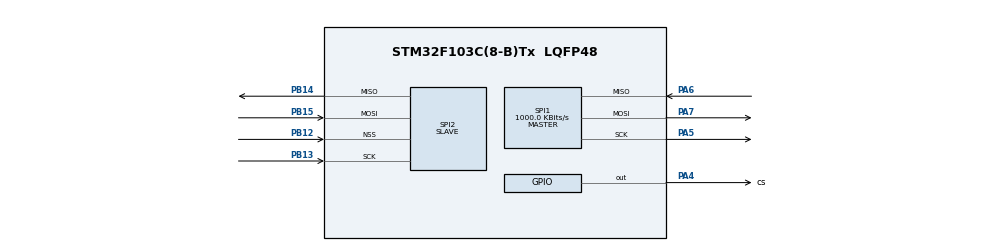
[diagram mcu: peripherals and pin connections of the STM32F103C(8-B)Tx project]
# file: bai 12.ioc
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Dma.Request0=SPI2_RX
Dma.SPI2_RX.0.Direction=DMA_PERIPH_TO_MEMORY
Dma.SPI2_RX.0.Instance=DMA1_Channel4
Dma.SPI2_RX.0.MemDataAlignment=DMA_MDATAALIGN_BYTE
Dma.SPI2_RX.0.MemInc=DMA_MINC_ENABLE
Dma.SPI2_RX.0.Mode=DMA_CIRCULAR
Dma.SPI2_RX.0.PeriphDataAlignment=DMA_PDATAALIGN_BYTE
Dma.SPI2_RX.0.PeriphInc=DMA_PINC_DISABLE
Dma.SPI2_RX.0.Priority=DMA_PRIORITY_LOW
Mcu.Family=STM32F1
Mcu.Name=STM32F103C(8-B)Tx
Mcu.Package=LQFP48
NVIC.DMA1_Channel4_IRQn=true\:0\:0\:false\:false\:true\:false\:true\:true
NVIC.PriorityGroup=NVIC_PRIORITYGROUP_4
NVIC.SPI1_IRQn=true\:0\:0\:false\:false\:true\:true\:true\:true
NVIC.SPI2_IRQn=true\:0\:0\:false\:false\:true\:true\:true\:true
PA13.Mode=Serial_Wire
PA13.Signal=SYS_JTMS-SWDIO
PA14.Mode=Serial_Wire
PA14.Signal=SYS_JTCK-SWCLK
PA4.GPIO_Label=cs
PA4.PinState=GPIO_PIN_SET
PA4.Signal=GPIO_Output
PA5.Mode=Full_Duplex_Master
PA5.Signal=SPI1_SCK
PA6.Mode=Full_Duplex_Master
PA6.Signal=SPI1_MISO
PA7.Mode=Full_Duplex_Master
PA7.Signal=SPI1_MOSI
PB12.Mode=NSS_Signal_Hard_Input
PB12.Signal=SPI2_NSS
PB13.Mode=Full_Duplex_Slave
PB13.Signal=SPI2_SCK
PB14.Mode=Full_Duplex_Slave
PB14.Signal=SPI2_MISO
PB15.Mode=Full_Duplex_Slave
PB15.Signal=SPI2_MOSI
ProjectManager.HeapSize=0x200
ProjectManager.StackSize=0x400
ProjectManager.TargetToolchain=MDK-ARM V5.32
RCC.APB1Freq_Value=8000000
RCC.APB2Freq_Value=8000000
SPI1.BaudRatePrescaler=SPI_BAUDRATEPRESCALER_8
SPI1.CalculateBaudRate=1000.0 KBits/s
SPI1.Direction=SPI_DIRECTION_2LINES
SPI1.Mode=SPI_MODE_MASTER
SPI1.VirtualType=VM_MASTER
SPI2.CLKPolarity=SPI_POLARITY_LOW
SPI2.Direction=SPI_DIRECTION_2LINES
SPI2.Mode=SPI_MODE_SLAVE
SPI2.VirtualNSS=VM_NSSHARD
SPI2.VirtualType=VM_SLAVE
board=custom

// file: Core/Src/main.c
/* USER CODE BEGIN Header */
/**
  ******************************************************************************
  * @file           : main.c
  * @brief          : Main program body
  ******************************************************************************
  * @attention
  *
  * Copyright (c) 2024 STMicroelectronics.
  * All rights reserved.
  *
  * This software is licensed under terms that can be found in the LICENSE file
  * in the root directory of this software component.
  * If no LICENSE file comes with this software, it is provided AS-IS.
  *
  ******************************************************************************
  */
/* USER CODE END Header */
#include "main.h"

/* USER CODE BEGIN Includes */
#include "stdio.h"
#define sizeofBuff 20
uint8_t u8_SPI1_TxBuff[sizeofBuff] = "Master send";
uint8_t u8_SPI2_RxBuff[sizeofBuff];
uint8_t count;

/* USER CODE END Includes */

SPI_HandleTypeDef hspi1;
SPI_HandleTypeDef hspi2;
DMA_HandleTypeDef hdma_spi2_rx;

void SystemClock_Config(void);
static void MX_GPIO_Init(void);
static void MX_DMA_Init(void);
static void MX_SPI1_Init(void);
static void MX_SPI2_Init(void);

/* USER CODE BEGIN 0 */

//void HAL_SPI_RxCpltCallback(SPI_HandleTypeDef *hspi)
//{
//	if(hspi->Instance == SPI2)
//	{
//		HAL_SPI_Receive_IT(&hspi2, u8_SPI2_RxBuff, sizeofBuff);
//	}
//}

/* USER CODE END 0 */

int main(void)
{

  /* MCU Configuration--------------------------------------------------------*/

  /* Reset of all peripherals, Initializes the Flash interface and the Systick. */
  HAL_Init();

  /* Configure the system clock */
  SystemClock_Config();

  /* Initialize all configured peripherals */
  MX_GPIO_Init();
  MX_DMA_Init();
  MX_SPI1_Init();
  MX_SPI2_Init();
  /* USER CODE BEGIN 2 */
	HAL_SPI_Receive_DMA(&hspi2, u8_SPI2_RxBuff, sizeofBuff);
//	HAL_SPI_Receive_IT(&hspi2, u8_SPI2_RxBuff, sizeofBuff);
	HAL_SPI_Transmit(&hspi1, u8_SPI1_TxBuff, sizeofBuff, 100);
  /* USER CODE END 2 */

  /* Infinite loop */
  while (1)
  {

    /* USER CODE BEGIN 3 */
		sprintf((char*) u8_SPI1_TxBuff, "gui lan thu %d: ", count);
		HAL_GPIO_WritePin(cs_GPIO_Port, cs_Pin, GPIO_PIN_RESET);
		HAL_SPI_Transmit(&hspi1, u8_SPI1_TxBuff, sizeofBuff, 100);
		HAL_GPIO_WritePin(cs_GPIO_Port, cs_Pin, GPIO_PIN_SET);
		count++;
		HAL_Delay(1000);

  }
  /* USER CODE END 3 */
}

void SystemClock_Config(void)
{
  RCC_OscInitTypeDef RCC_OscInitStruct = {0};
  RCC_ClkInitTypeDef RCC_ClkInitStruct = {0};

  /** Initializes the RCC Oscillators according to the specified parameters
  * in the RCC_OscInitTypeDef structure.
  */
  RCC_OscInitStruct.OscillatorType = RCC_OSCILLATORTYPE_HSI;
  RCC_OscInitStruct.HSIState = RCC_HSI_ON;
  RCC_OscInitStruct.HSICalibrationValue = RCC_HSICALIBRATION_DEFAULT;
  RCC_OscInitStruct.PLL.PLLState = RCC_PLL_NONE;
  if (HAL_RCC_OscConfig(&RCC_OscInitStruct) != HAL_OK)
  {
    Error_Handler();
  }

  /** Initializes the CPU, AHB and APB buses clocks
  */
  RCC_ClkInitStruct.ClockType = RCC_CLOCKTYPE_HCLK|RCC_CLOCKTYPE_SYSCLK
                              |RCC_CLOCKTYPE_PCLK1|RCC_CLOCKTYPE_PCLK2;
  RCC_ClkInitStruct.SYSCLKSource = RCC_SYSCLKSOURCE_HSI;
  RCC_ClkInitStruct.AHBCLKDivider = RCC_SYSCLK_DIV1;
  RCC_ClkInitStruct.APB1CLKDivider = RCC_HCLK_DIV1;
  RCC_ClkInitStruct.APB2CLKDivider = RCC_HCLK_DIV1;

  if (HAL_RCC_ClockConfig(&RCC_ClkInitStruct, FLASH_LATENCY_0) != HAL_OK)
  {
    Error_Handler();
  }
}

static void MX_SPI1_Init(void)
{

  /* SPI1 parameter configuration*/
  hspi1.Instance = SPI1;
  hspi1.Init.Mode = SPI_MODE_MASTER;
  hspi1.Init.Direction = SPI_DIRECTION_2LINES;
  hspi1.Init.DataSize = SPI_DATASIZE_8BIT;
  hspi1.Init.CLKPolarity = SPI_POLARITY_LOW;
  hspi1.Init.CLKPhase = SPI_PHASE_1EDGE;
  hspi1.Init.NSS = SPI_NSS_SOFT;
  hspi1.Init.BaudRatePrescaler = SPI_BAUDRATEPRESCALER_8;
  hspi1.Init.FirstBit = SPI_FIRSTBIT_MSB;
  hspi1.Init.TIMode = SPI_TIMODE_DISABLE;
  hspi1.Init.CRCCalculation = SPI_CRCCALCULATION_DISABLE;
  hspi1.Init.CRCPolynomial = 10;
  if (HAL_SPI_Init(&hspi1) != HAL_OK)
  {
    Error_Handler();
  }

}

static void MX_SPI2_Init(void)
{

  /* SPI2 parameter configuration*/
  hspi2.Instance = SPI2;
  hspi2.Init.Mode = SPI_MODE_SLAVE;
  hspi2.Init.Direction = SPI_DIRECTION_2LINES;
  hspi2.Init.DataSize = SPI_DATASIZE_8BIT;
  hspi2.Init.CLKPolarity = SPI_POLARITY_LOW;
  hspi2.Init.CLKPhase = SPI_PHASE_1EDGE;
  hspi2.Init.NSS = SPI_NSS_HARD_INPUT;
  hspi2.Init.FirstBit = SPI_FIRSTBIT_MSB;
  hspi2.Init.TIMode = SPI_TIMODE_DISABLE;
  hspi2.Init.CRCCalculation = SPI_CRCCALCULATION_DISABLE;
  hspi2.Init.CRCPolynomial = 10;
  if (HAL_SPI_Init(&hspi2) != HAL_OK)
  {
    Error_Handler();
  }

}

static void MX_DMA_Init(void)
{

  /* DMA controller clock enable */
  __HAL_RCC_DMA1_CLK_ENABLE();

  /* DMA interrupt init */
  /* DMA1_Channel4_IRQn interrupt configuration */
  HAL_NVIC_SetPriority(DMA1_Channel4_IRQn, 0, 0);
  HAL_NVIC_EnableIRQ(DMA1_Channel4_IRQn);

}

static void MX_GPIO_Init(void)
{
  GPIO_InitTypeDef GPIO_InitStruct = {0};

  /* GPIO Ports Clock Enable */
  __HAL_RCC_GPIOA_CLK_ENABLE();
  __HAL_RCC_GPIOB_CLK_ENABLE();

  /*Configure GPIO pin Output Level */
  HAL_GPIO_WritePin(cs_GPIO_Port, cs_Pin, GPIO_PIN_SET);

  /*Configure GPIO pin : cs_Pin */
  GPIO_InitStruct.Pin = cs_Pin;
  GPIO_InitStruct.Mode = GPIO_MODE_OUTPUT_PP;
  GPIO_InitStruct.Pull = GPIO_NOPULL;
  GPIO_InitStruct.Speed = GPIO_SPEED_FREQ_LOW;
  HAL_GPIO_Init(cs_GPIO_Port, &GPIO_InitStruct);

}

void Error_Handler(void)
{
  __disable_irq();
  while (1)
  {
  }
}
